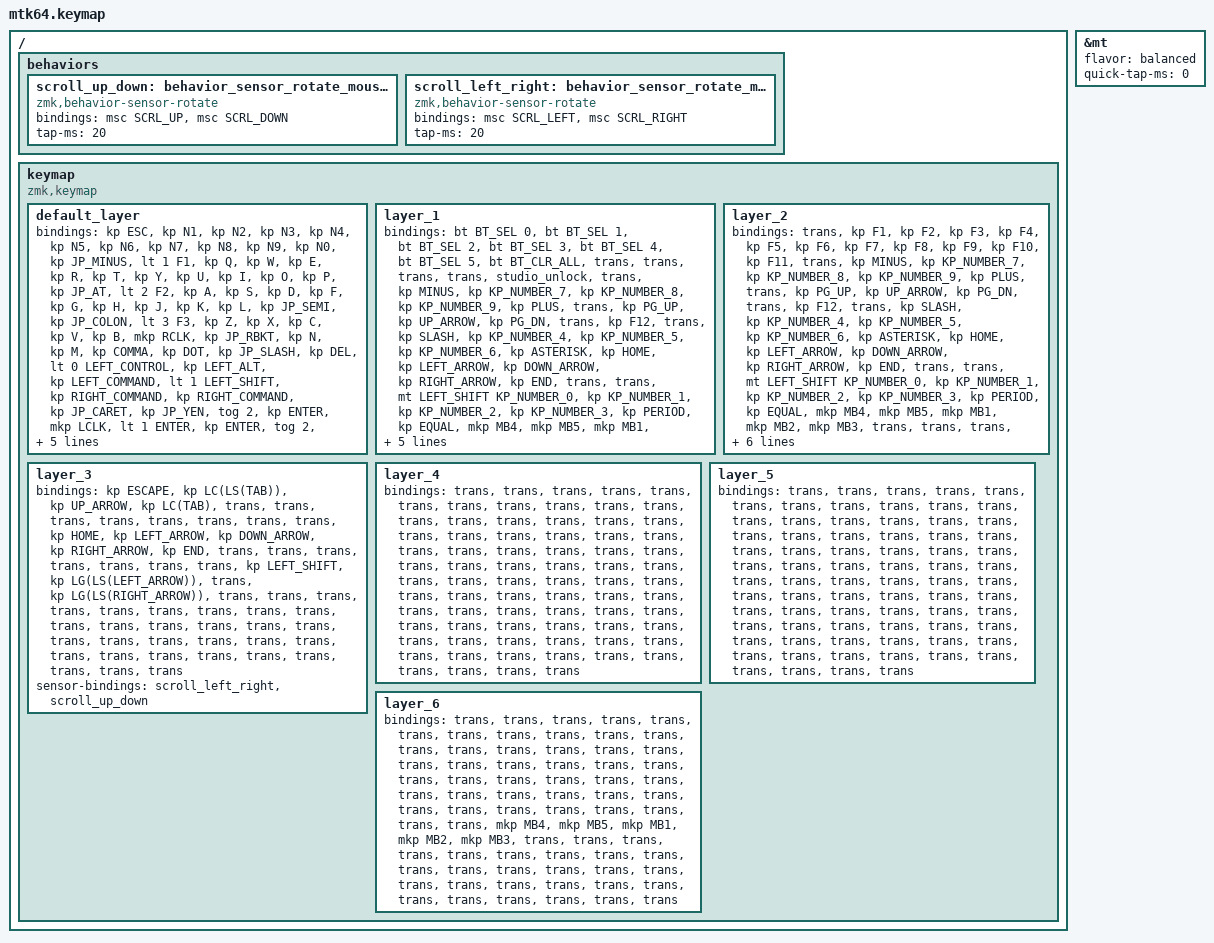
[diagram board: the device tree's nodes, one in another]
#include <behaviors.dtsi>
#include <dt-bindings/zmk/bt.h>
#include <dt-bindings/zmk/keys.h>
#include <dt-bindings/zmk/pointing.h>
#include "keycode_japanese.h"

// スクロール量の設定

#define ZMK_POINTING_DEFAULT_SCRL_VAL 100

&mt {
    flavor = "balanced";
    quick-tap-ms = <0>;
};

/ {
    behaviors {
        // 垂直スクロール用のbehaviorの設定

        scroll_up_down: behavior_sensor_rotate_mouse_wheel_up_down {
            compatible = "zmk,behavior-sensor-rotate";
            #sensor-binding-cells = <0>;
            bindings = <&msc SCRL_UP>, <&msc SCRL_DOWN>;

            tap-ms = <20>; // スクロールのタップ時間
        };

        // 水平スクロール用のbehaviorの設定

        scroll_left_right: behavior_sensor_rotate_mouse_wheel_left_right {
            compatible = "zmk,behavior-sensor-rotate";
            #sensor-binding-cells = <0>;
            bindings = <&msc SCRL_LEFT>, <&msc SCRL_RIGHT>;

            tap-ms = <20>; // スクロールのタップ時間
        };
    };
};

/ {
    keymap {
        compatible = "zmk,keymap";

        default_layer {
            bindings = <
&kp ESC  &kp N1  &kp N2  &kp N3  &kp N4  &kp N5  &kp N6  &kp N7  &kp N8  &kp N9  &kp N0  &kp JP_MINUS  &lt 1 F1  &kp Q  &kp W  &kp E  &kp R  &kp T  &kp Y  &kp U  &kp I  &kp O  &kp P  &kp JP_AT  &lt 2 F2  &kp A  &kp S  &kp D  &kp F  &kp G  &kp H  &kp J  &kp K  &kp L  &kp JP_SEMI  &kp JP_COLON  &lt 3 F3  &kp Z  &kp X  &kp C  &kp V  &kp B  &mkp RCLK  &kp JP_RBKT  &kp N  &kp M  &kp COMMA  &kp DOT  &kp JP_SLASH  &kp DEL  &lt 0 LEFT_CONTROL  &kp LEFT_ALT  &kp LEFT_COMMAND  &lt 1 LEFT_SHIFT  &kp RIGHT_COMMAND  &kp RIGHT_COMMAND  &kp JP_CARET  &kp JP_YEN  &tog 2  &kp ENTER  &mkp LCLK  &lt 1 ENTER  &kp ENTER  &tog 2  &kp SPACE  &kp LG(V)  &mo 1  &mo 2  &mo 3  &mo 1  &mo 2  &mo 3  &mo 1  &mo 2  &mo 3
            >;

            sensor-bindings = <
                &inc_dec_kp LEFT_ARROW RIGHT_ARROW
                &inc_dec_kp UP_ARROW   DOWN_ARROW
            >;
        };

        layer_1 {
            bindings = <
&bt BT_SEL 0  &bt BT_SEL 1  &bt BT_SEL 2  &bt BT_SEL 3  &bt BT_SEL 4  &bt BT_SEL 5  &bt BT_CLR_ALL  &trans  &trans  &trans  &trans  &studio_unlock  &trans  &kp MINUS  &kp KP_NUMBER_7  &kp KP_NUMBER_8  &kp KP_NUMBER_9  &kp PLUS  &trans  &kp PG_UP  &kp UP_ARROW  &kp PG_DN  &trans  &kp F12  &trans  &kp SLASH  &kp KP_NUMBER_4  &kp KP_NUMBER_5  &kp KP_NUMBER_6  &kp ASTERISK  &kp HOME  &kp LEFT_ARROW  &kp DOWN_ARROW  &kp RIGHT_ARROW  &kp END  &trans  &trans  &mt LEFT_SHIFT KP_NUMBER_0  &kp KP_NUMBER_1  &kp KP_NUMBER_2  &kp KP_NUMBER_3  &kp PERIOD  &kp EQUAL  &mkp MB4  &mkp MB5  &mkp MB1  &mkp MB2  &mkp MB3  &trans  &trans  &trans  &trans  &trans  &trans  &trans  &trans  &trans  &trans  &trans  &trans  &trans  &trans  &trans  &trans  &trans  &trans  &trans  &trans  &trans  &trans  &trans  &trans  &trans  &trans  &trans
            >;
        };

        layer_2 {
            bindings = <
&trans  &kp F1  &kp F2  &kp F3  &kp F4  &kp F5  &kp F6  &kp F7  &kp F8  &kp F9  &kp F10  &kp F11  &trans  &kp MINUS  &kp KP_NUMBER_7  &kp KP_NUMBER_8  &kp KP_NUMBER_9  &kp PLUS  &trans  &kp PG_UP  &kp UP_ARROW  &kp PG_DN  &trans  &kp F12  &trans  &kp SLASH  &kp KP_NUMBER_4  &kp KP_NUMBER_5  &kp KP_NUMBER_6  &kp ASTERISK  &kp HOME  &kp LEFT_ARROW  &kp DOWN_ARROW  &kp RIGHT_ARROW  &kp END  &trans  &trans  &mt LEFT_SHIFT KP_NUMBER_0  &kp KP_NUMBER_1  &kp KP_NUMBER_2  &kp KP_NUMBER_3  &kp PERIOD  &kp EQUAL  &mkp MB4  &mkp MB5  &mkp MB1  &mkp MB2  &mkp MB3  &trans  &trans  &trans  &trans  &trans  &trans  &trans  &trans  &trans  &trans  &trans  &trans  &trans  &trans  &trans  &trans  &trans  &trans  &trans  &trans  &trans  &trans  &trans  &trans  &trans  &trans  &trans
            >;

            sensor-bindings = <
                &inc_dec_kp TAB LC(TAB) 
                &inc_dec_kp PG_UP PG_DN
            >;
        };

        layer_3 {
            bindings = <
&kp ESCAPE  &kp LC(LS(TAB))  &kp UP_ARROW  &kp LC(TAB)  &trans  &trans  &trans  &trans  &trans  &trans  &trans  &trans  &kp HOME  &kp LEFT_ARROW  &kp DOWN_ARROW  &kp RIGHT_ARROW  &kp END  &trans  &trans  &trans  &trans  &trans  &trans  &trans  &kp LEFT_SHIFT  &kp LG(LS(LEFT_ARROW))  &trans  &kp LG(LS(RIGHT_ARROW))  &trans  &trans  &trans  &trans  &trans  &trans  &trans  &trans  &trans  &trans  &trans  &trans  &trans  &trans  &trans  &trans  &trans  &trans  &trans  &trans  &trans  &trans  &trans  &trans  &trans  &trans  &trans  &trans  &trans  &trans
            >;

            sensor-bindings = <
                &scroll_left_right
                &scroll_up_down
            >;
        };

        layer_4 {
            bindings = <
&trans  &trans  &trans  &trans  &trans  &trans  &trans  &trans  &trans  &trans  &trans  &trans  &trans  &trans  &trans  &trans  &trans  &trans  &trans  &trans  &trans  &trans  &trans  &trans  &trans  &trans  &trans  &trans  &trans  &trans  &trans  &trans  &trans  &trans  &trans  &trans  &trans  &trans  &trans  &trans  &trans  &trans  &trans  &trans  &trans  &trans  &trans  &trans  &trans  &trans  &trans  &trans  &trans  &trans  &trans  &trans  &trans  &trans  &trans  &trans  &trans  &trans  &trans  &trans  &trans  &trans  &trans  &trans  &trans  &trans  &trans  &trans  &trans  &trans  &trans
            >;
        };

        layer_5 {
            bindings = <
&trans  &trans  &trans  &trans  &trans  &trans  &trans  &trans  &trans  &trans  &trans  &trans  &trans  &trans  &trans  &trans  &trans  &trans  &trans  &trans  &trans  &trans  &trans  &trans  &trans  &trans  &trans  &trans  &trans  &trans  &trans  &trans  &trans  &trans  &trans  &trans  &trans  &trans  &trans  &trans  &trans  &trans  &trans  &trans  &trans  &trans  &trans  &trans  &trans  &trans  &trans  &trans  &trans  &trans  &trans  &trans  &trans  &trans  &trans  &trans  &trans  &trans  &trans  &trans  &trans  &trans  &trans  &trans  &trans  &trans  &trans  &trans  &trans  &trans  &trans
            >;
        };

        layer_6 {
            bindings = <
&trans  &trans  &trans  &trans  &trans  &trans  &trans  &trans  &trans  &trans  &trans  &trans  &trans  &trans  &trans  &trans  &trans  &trans  &trans  &trans  &trans  &trans  &trans  &trans  &trans  &trans  &trans  &trans  &trans  &trans  &trans  &trans  &trans  &trans  &trans  &trans  &trans  &trans  &trans  &trans  &trans  &trans  &trans  &mkp MB4  &mkp MB5  &mkp MB1  &mkp MB2  &mkp MB3  &trans  &trans  &trans  &trans  &trans  &trans  &trans  &trans  &trans  &trans  &trans  &trans  &trans  &trans  &trans  &trans  &trans  &trans  &trans  &trans  &trans  &trans  &trans  &trans  &trans  &trans  &trans
            >;
        };
    };
};
